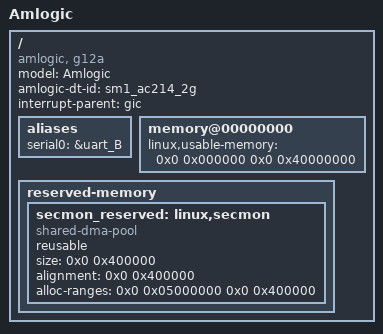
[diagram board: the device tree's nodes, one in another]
/*
 * arch/arm64/boot/dts/amlogic/sc2_pxp.dts
 *
 * Copyright (C) 2017 Amlogic, Inc. All rights reserved.
 *
 * This program is free software; you can redistribute it and/or modify
 * it under the terms of the GNU General Public License as published by
 * the Free Software Foundation; either version 2 of the License, or
 * (at your option) any later version.
 *
 * This program is distributed in the hope that it will be useful, but WITHOUT
 * ANY WARRANTY; without even the implied warranty of MERCHANTABILITY or
 * FITNESS FOR A PARTICULAR PURPOSE.  See the GNU General Public License for
 * more details.
 *
 */

/dts-v1/;

#include "mesonsc2_pxp.dtsi"

/ {
	model = "Amlogic";
	amlogic-dt-id = "sm1_ac214_2g";
	compatible = "amlogic, g12a";
	interrupt-parent = <&gic>;
	#address-cells = <2>;
	#size-cells = <2>;

	aliases {
		serial0 = &uart_B;
	};

	memory@00000000 {
		device_type = "memory";
		linux,usable-memory = <0x0 0x000000 0x0 0x40000000>;
	};

	reserved-memory {
		#address-cells = <2>;
		#size-cells = <2>;
		ranges;

		secmon_reserved:linux,secmon {
			compatible = "shared-dma-pool";
			reusable;
			size = <0x0 0x400000>;
			alignment = <0x0 0x400000>;
			alloc-ranges = <0x0 0x05000000 0x0 0x400000>;
		};
	};
};
